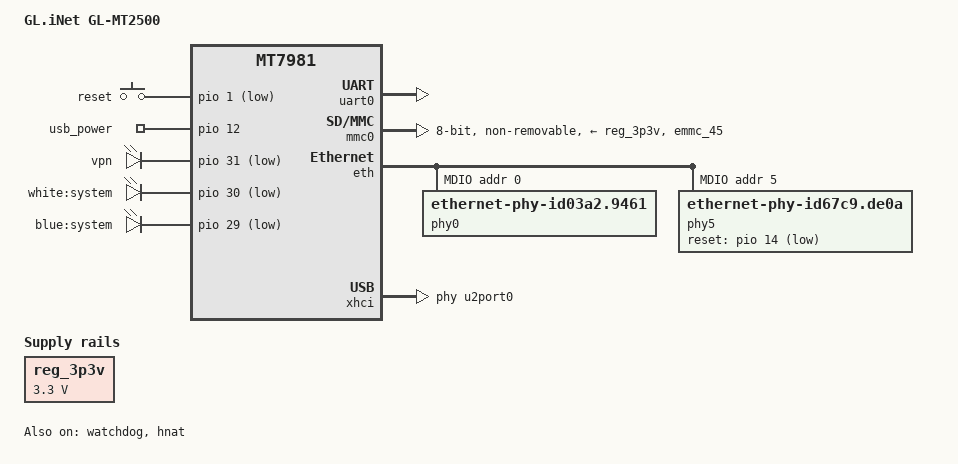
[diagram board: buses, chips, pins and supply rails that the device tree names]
/dts-v1/;
#include "mt7981.dtsi"
/ {
	model = "GL.iNet GL-MT2500";
	compatible = "glinet,mt2500-emmc", "mediatek,mt7981";

	chosen {
		bootargs = "console=ttyS0,115200n1 loglevel=8  \
				earlycon=uart8250,mmio32,0x11002000 \
				root=PARTLABEL=rootfs rootwait rootfstype=squashfs,f2fs \
				block2mtd.block2mtd=/dev/mmcblk0p1,65536,log";
	};

	reg_3p3v: regulator-3p3v {
		compatible = "regulator-fixed";
		regulator-name = "fixed-3.3V";
		regulator-min-microvolt = <3300000>;
		regulator-max-microvolt = <3300000>;
		regulator-boot-on;
		regulator-always-on;
	};

	gl-hw {
		compatible = "gl-hw-info";
		model = "mt2500";
		wan = "eth0";
		lan = "eth1";
		usb-port = "1-1";
		flash_size = <8192>;
		temperature = "/sys/devices/virtual/thermal/thermal_zone0/temp";
		factory_data {
			device_mac = "/dev/mmcblk0boot1", "0x0a";
			device_ddns = "/dev/mmcblk0boot1", "0x10";
			device_sn_bak = "/dev/mmcblk0boot1", "0x20";
			device_sn = "/dev/mmcblk0boot1", "0x30";
		};
	};

	gpio-keys {
		compatible = "gpio-keys";

		reset {
			label = "reset";
			linux,code = <KEY_RESTART>;
			gpios = <&pio 1 GPIO_ACTIVE_LOW>;
		};
	};

	gpio-export {
		compatible = "gpio-export";

		usb_power {
			gpio-export,name = "usb_power";
			gpio-export,output = <1>;
			gpios = <&pio 12 GPIO_ACTIVE_HIGH>;
		};
	};

	leds {
		compatible = "gpio-leds";

		led@0 {
			label = "vpn";
			gpios = <&pio 31 GPIO_ACTIVE_LOW>;
		};

		led@1 {
			label = "white:system";
			gpios = <&pio 30 GPIO_ACTIVE_LOW>;
		};

		led@2 {
			label = "blue:system";
			gpios = <&pio 29 GPIO_ACTIVE_LOW>;
			default-state = "on";
		};
	};
};

&uart0 {
	status = "okay";
};

&watchdog {
	status = "okay";
};

&mmc0 {
         pinctrl-names = "default", "state_uhs";
         pinctrl-0 = <&mmc0_pins_default>;
         pinctrl-1 = <&mmc0_pins_uhs>;
         bus-width = <8>;
         max-frequency = <52000000>;
         cap-mmc-highspeed;
         vmmc-supply = <&reg_3p3v>;
         non-removable;
         status = "okay";
};

&eth {
	status = "okay";

	gmac0: mac@0 {
		compatible = "mediatek,eth-mac";
		reg = <0>;
		phy-mode = "2500base-x";
		fixed-link {
			speed = <2500>;
			full-duplex;
			pause;
		};
	};

	gmac1: mac@1 {
		compatible = "mediatek,eth-mac";
		reg = <1>;
		phy-mode = "gmii";
		fixed-link {
			speed = <1000>;
			phy-handle = <&phy0>;
			full-duplex;
			pause;
		};
	};

	mdio: mdio-bus {
		#address-cells = <1>;
		#size-cells = <0>;

		phy0: ethernet-phy@0 {
			compatible = "ethernet-phy-id03a2.9461";
			reg = <0>;
			phy-mode = "gmii";
			nvmem-cells = <&phy_calibration>;
			nvmem-cell-names = "phy-cal-data";
		};

		phy5: phy@5 {
			compatible = "ethernet-phy-id67c9.de0a";
			reg = <5>;
			reset-gpios = <&pio 14 1>;
			reset-assert-us = <600>;
			reset-deassert-us = <20000>;
		};
	};
};

&hnat {
	mtketh-wan = "eth1";
	mtketh-lan = "eth0";
	mtketh-ppd = "eth0";
	mtketh-max-gmac = <2>;
	status = "okay";
};

&spi1 {
	pinctrl-names = "default";
	pinctrl-0 = <&spic_pins>;
	status = "disabled";
};

&pio {
	spic_pins: spi1-pins {
		mux {
			function = "spi";
			groups = "spi1_1";
		};
	};
	mmc0_pins_default: mmc0-pins-default {
		mux {
			function = "flash";
			groups = "emmc_45";
		};
	};
	mmc0_pins_uhs: mmc0-pins-uhs {
		mux {
			function = "flash";
			groups = "emmc_45";
		};
	};
};

&xhci {
	mediatek,u3p-dis-msk = <0x0>;
	phys = <&u2port0 PHY_TYPE_USB2>,
	       <&u3port0 PHY_TYPE_USB3>;
	status = "okay";
};
